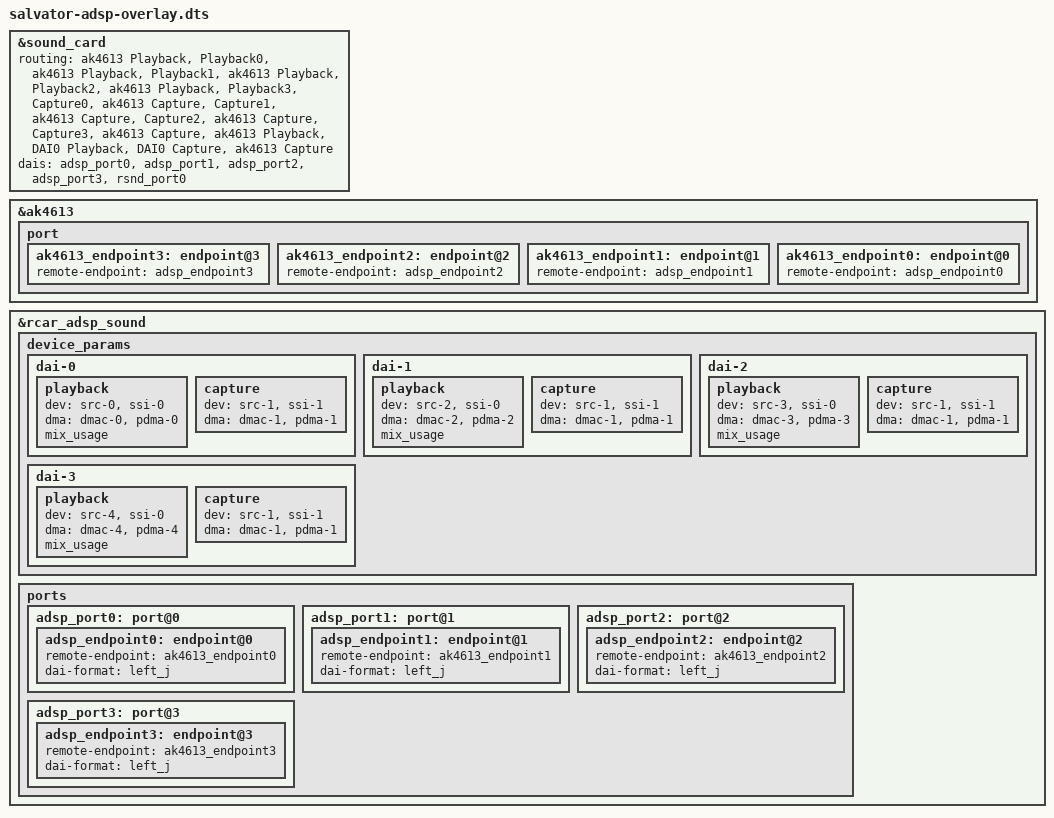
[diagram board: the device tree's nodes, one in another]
/*
 * Device Tree Overlay for the Salvator boards with enabled ADSP
 *
 * Copyright (C) 2018 GlobalLogic
 *
 * This file is licensed under the terms of the GNU General Public License
 * version 2.  This program is licensed "as is" without any warranty of any
 * kind, whether express or implied.
 */

/dts-v1/;
/plugin/;

&sound_card {
	routing = "ak4613 Playback", "Playback0",
			"ak4613 Playback", "Playback1",
			"ak4613 Playback", "Playback2",
			"ak4613 Playback", "Playback3",
			"Capture0", "ak4613 Capture",
			"Capture1", "ak4613 Capture",
			"Capture2", "ak4613 Capture",
			"Capture3", "ak4613 Capture",
			"ak4613 Playback", "DAI0 Playback",
			"DAI0 Capture", "ak4613 Capture";

	dais = <&adsp_port0
		&adsp_port1
		&adsp_port2
		&adsp_port3
		&rsnd_port0>;
};

&ak4613 {
	port {
		/* In case of ADSP overlay these EPs appear in reverse order,
		 * so asoc-audio-graph-scu-card fails to parse DT. Avoid this by
		 * placing EPs in such below order
		 */
		ak4613_endpoint3: endpoint@3 {
			remote-endpoint = <&adsp_endpoint3>;
		};
		ak4613_endpoint2: endpoint@2 {
			remote-endpoint = <&adsp_endpoint2>;
		};
		ak4613_endpoint1: endpoint@1 {
			remote-endpoint = <&adsp_endpoint1>;
		};
		ak4613_endpoint0: endpoint@0 {
			remote-endpoint = <&adsp_endpoint0>;
		};
	};
};

&rcar_adsp_sound {
	status = "okay";
	/* Multiple DAI */
	#sound-dai-cells = <1>;

	device_params {
		dai-0 {
			playback {
				dev = "src-0", "ssi-0";
				dma = "dmac-0", "pdma-0";
				mix_usage;
			};
			capture {
				dev = "src-1", "ssi-1";
				dma = "dmac-1", "pdma-1";
			};
		};
		dai-1 {
			playback {
				dev = "src-2", "ssi-0";
				dma = "dmac-2", "pdma-2";
				mix_usage;
			};
			capture {
				dev = "src-1", "ssi-1";
				dma = "dmac-1", "pdma-1";
			};
		};
		dai-2 {
			playback {
				dev = "src-3", "ssi-0";
				dma = "dmac-3", "pdma-3";
				mix_usage;
			};
			capture {
				dev = "src-1", "ssi-1";
				dma = "dmac-1", "pdma-1";
			};
		};
		dai-3 {
			playback {
				dev = "src-4", "ssi-0";
				dma = "dmac-4", "pdma-4";
				mix_usage;
			};
			capture {
				dev = "src-1", "ssi-1";
				dma = "dmac-1", "pdma-1";
			};
		};
	};

	ports {
		adsp_port0: port@0 {
			adsp_endpoint0: endpoint@0 {
				remote-endpoint = <&ak4613_endpoint0>;
				dai-format = "left_j";
			};
		};
		adsp_port1: port@1 {
			adsp_endpoint1: endpoint@1 {
				remote-endpoint = <&ak4613_endpoint1>;
				dai-format = "left_j";
			};
		};
		adsp_port2: port@2 {
			adsp_endpoint2: endpoint@2 {
				remote-endpoint = <&ak4613_endpoint2>;
				dai-format = "left_j";
			};
		};
		adsp_port3: port@3 {
			adsp_endpoint3: endpoint@3 {
				remote-endpoint = <&ak4613_endpoint3>;
				dai-format = "left_j";
			};
		};
	};
};
